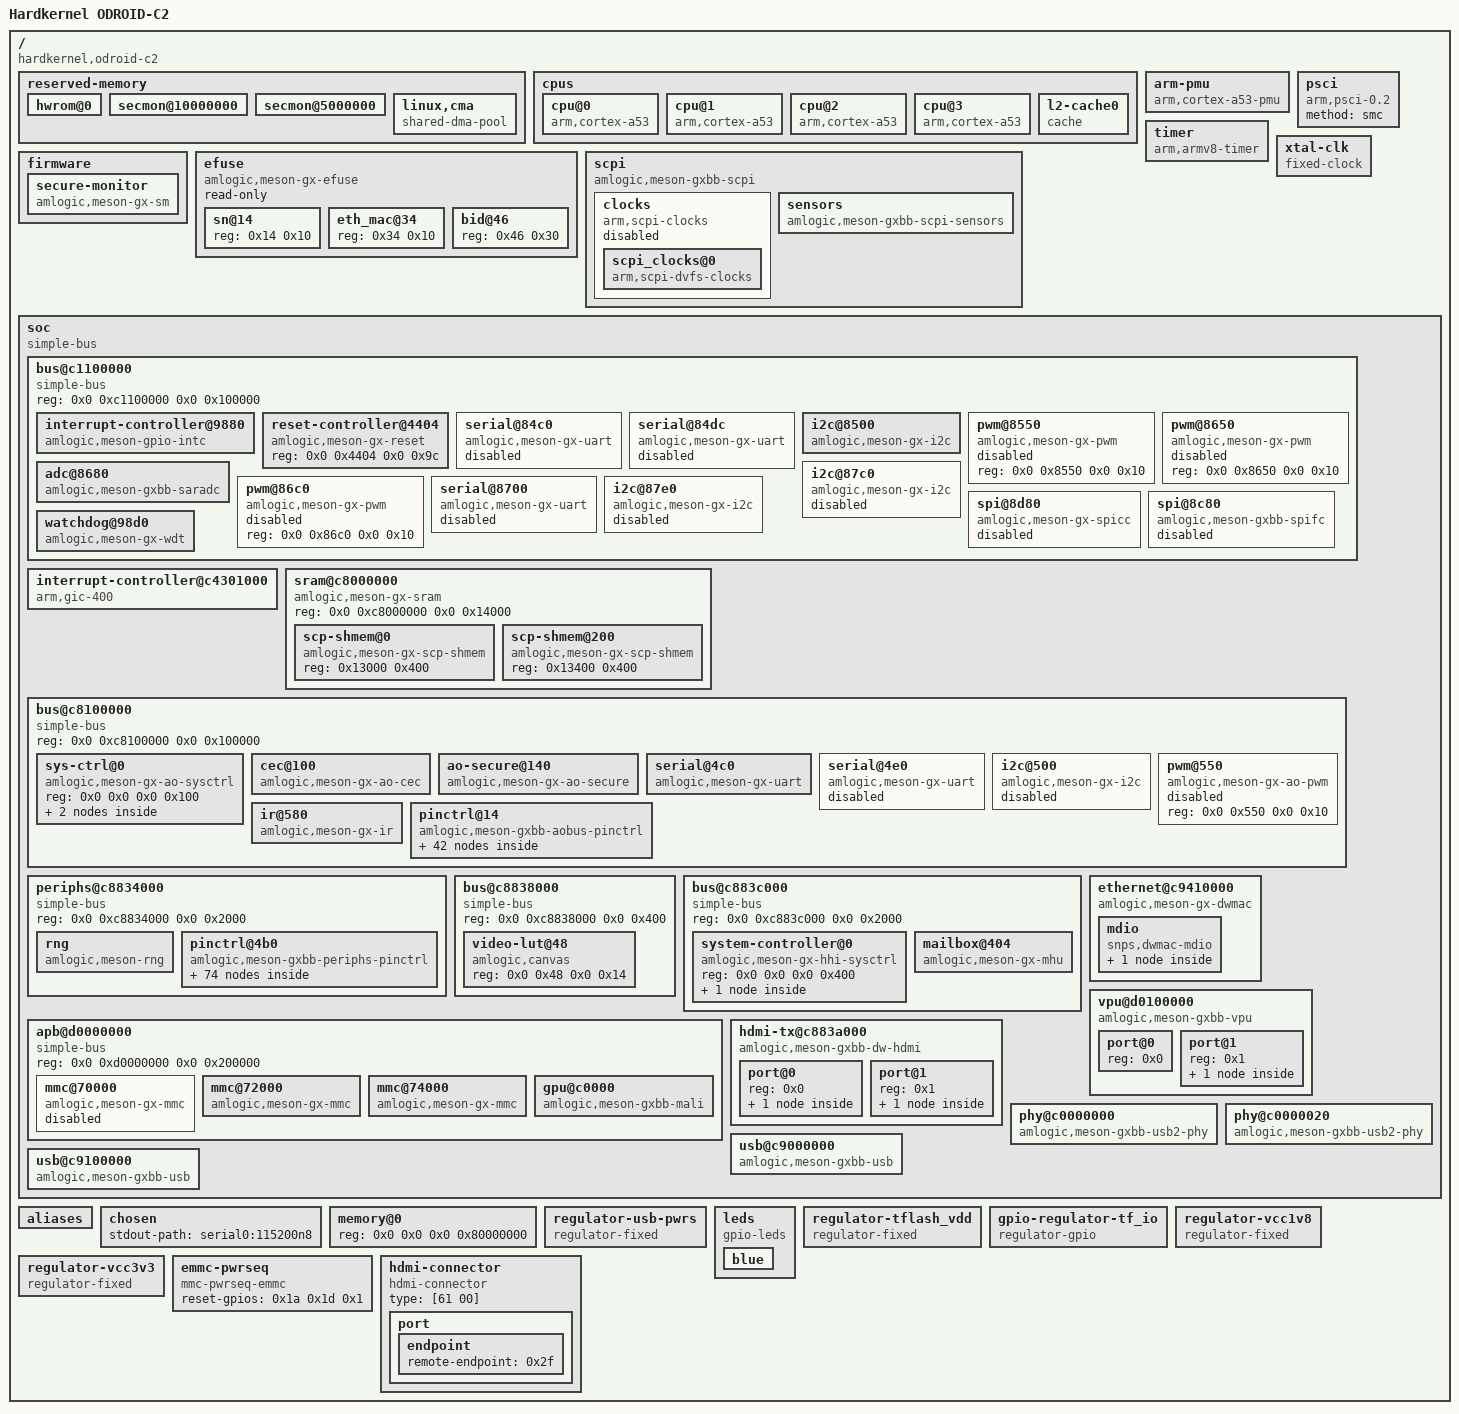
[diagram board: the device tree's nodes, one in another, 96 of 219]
/*
 * The code contained herein is licensed under the GNU General Public
 * License. You may obtain a copy of the GNU General Public License
 * Version 2 or later at the following locations:
 *
 * http://www.opensource.org/licenses/gpl-license.html
 * http://www.gnu.org/copyleft/gpl.html
 *
 * @TAG(OTHER_GPL)
 */

/dts-v1/;

/ {
	interrupt-parent = <0x1>;
	#address-cells = <0x2>;
	#size-cells = <0x2>;
	compatible = "hardkernel,odroid-c2", "amlogic,meson-gxbb";
	model = "Hardkernel ODROID-C2";

	reserved-memory {
		#address-cells = <0x2>;
		#size-cells = <0x2>;
		ranges;

		hwrom@0 {
			reg = <0x0 0x0 0x0 0x1000000>;
			no-map;
		};

		secmon@10000000 {
			reg = <0x0 0x10000000 0x0 0x200000>;
			no-map;
		};

		secmon@5000000 {
			reg = <0x0 0x5000000 0x0 0x300000>;
			no-map;
		};

		linux,cma {
			compatible = "shared-dma-pool";
			reusable;
			size = <0x0 0x10000000>;
			alignment = <0x0 0x400000>;
			linux,cma-default;
		};
	};

	cpus {
		#address-cells = <0x2>;
		#size-cells = <0x0>;

		cpu@0 {
			device_type = "cpu";
			compatible = "arm,cortex-a53", "arm,armv8";
			reg = <0x0 0x0>;
			enable-method = "psci";
			next-level-cache = <0x2>;
			clocks = <0x3 0x0>;
			phandle = <0x4>;
		};

		cpu@1 {
			device_type = "cpu";
			compatible = "arm,cortex-a53", "arm,armv8";
			reg = <0x0 0x1>;
			enable-method = "psci";
			next-level-cache = <0x2>;
			clocks = <0x3 0x0>;
			phandle = <0x5>;
		};

		cpu@2 {
			device_type = "cpu";
			compatible = "arm,cortex-a53", "arm,armv8";
			reg = <0x0 0x2>;
			enable-method = "psci";
			next-level-cache = <0x2>;
			clocks = <0x3 0x0>;
			phandle = <0x6>;
		};

		cpu@3 {
			device_type = "cpu";
			compatible = "arm,cortex-a53", "arm,armv8";
			reg = <0x0 0x3>;
			enable-method = "psci";
			next-level-cache = <0x2>;
			clocks = <0x3 0x0>;
			phandle = <0x7>;
		};

		l2-cache0 {
			compatible = "cache";
			phandle = <0x2>;
		};
	};

	arm-pmu {
		compatible = "arm,cortex-a53-pmu";
		interrupts = <0x0 0x89 0x4 0x0 0x8a 0x4 0x0 0x99 0x4 0x0 0x9a 0x4>;
		interrupt-affinity = <0x4 0x5 0x6 0x7>;
	};

	psci {
		compatible = "arm,psci-0.2";
		method = "smc";
	};

	timer {
		compatible = "arm,armv8-timer";
		interrupts = <0x1 0xd 0xff08 0x1 0xe 0xff08 0x1 0xb 0xff08 0x1 0xa 0xff08>;
	};

	xtal-clk {
		compatible = "fixed-clock";
		clock-frequency = <0x16e3600>;
		clock-output-names = "xtal";
		#clock-cells = <0x0>;
		phandle = <0xb>;
	};

	firmware {

		secure-monitor {
			compatible = "amlogic,meson-gx-sm", "amlogic,meson-gxbb-sm";
		};
	};

	efuse {
		compatible = "amlogic,meson-gx-efuse", "amlogic,meson-gxbb-efuse";
		#address-cells = <0x1>;
		#size-cells = <0x1>;
		read-only;

		sn@14 {
			reg = <0x14 0x10>;
		};

		eth_mac@34 {
			reg = <0x34 0x10>;
		};

		bid@46 {
			reg = <0x46 0x30>;
		};
	};

	scpi {
		compatible = "amlogic,meson-gxbb-scpi", "arm,scpi-pre-1.0";
		mboxes = <0x8 0x1 0x8 0x2>;
		shmem = <0x9 0xa>;

		clocks {
			compatible = "arm,scpi-clocks";
			status = "disabled";

			scpi_clocks@0 {
				compatible = "arm,scpi-dvfs-clocks";
				#clock-cells = <0x1>;
				clock-indices = <0x0>;
				clock-output-names = "vcpu";
				phandle = <0x3>;
			};
		};

		sensors {
			compatible = "amlogic,meson-gxbb-scpi-sensors", "arm,scpi-sensors";
			#thermal-sensor-cells = <0x1>;
		};
	};

	soc {
		compatible = "simple-bus";
		#address-cells = <0x2>;
		#size-cells = <0x2>;
		ranges;

		bus@c1100000 {
			compatible = "simple-bus";
			reg = <0x0 0xc1100000 0x0 0x100000>;
			#address-cells = <0x2>;
			#size-cells = <0x2>;
			ranges = <0x0 0x0 0x0 0xc1100000 0x0 0x100000>;

			interrupt-controller@9880 {
				compatible = "amlogic,meson-gpio-intc", "amlogic,meson-gxbb-gpio-intc";
				reg = <0x0 0x9880 0x0 0x10>;
				interrupt-controller;
				#interrupt-cells = <0x2>;
				amlogic,channel-interrupts = <0x40 0x41 0x42 0x43 0x44 0x45 0x46 0x47>;
				status = "okay";
				phandle = <0x1b>;
			};

			reset-controller@4404 {
				compatible = "amlogic,meson-gx-reset", "amlogic,meson-gxbb-reset";
				reg = <0x0 0x4404 0x0 0x9c>;
				#reset-cells = <0x1>;
				phandle = <0xf>;
			};

			serial@84c0 {
				compatible = "amlogic,meson-gx-uart";
				reg = <0x0 0x84c0 0x0 0x18>;
				interrupts = <0x0 0x1a 0x1>;
				status = "disabled";
				clocks = <0xb 0xc 0x1a 0xb>;
				clock-names = "xtal", "pclk", "baud";
			};

			serial@84dc {
				compatible = "amlogic,meson-gx-uart";
				reg = <0x0 0x84dc 0x0 0x18>;
				interrupts = <0x0 0x4b 0x1>;
				status = "disabled";
				clocks = <0xb 0xc 0x30 0xb>;
				clock-names = "xtal", "pclk", "baud";
			};

			i2c@8500 {
				compatible = "amlogic,meson-gx-i2c", "amlogic,meson-gxbb-i2c";
				reg = <0x0 0x8500 0x0 0x20>;
				interrupts = <0x0 0x15 0x1>;
				#address-cells = <0x1>;
				#size-cells = <0x0>;
				status = "okay";
				clocks = <0xc 0x16>;
				pinctrl-0 = <0xd>;
				pinctrl-names = "default";
			};

			pwm@8550 {
				compatible = "amlogic,meson-gx-pwm", "amlogic,meson-gxbb-pwm";
				reg = <0x0 0x8550 0x0 0x10>;
				#pwm-cells = <0x3>;
				status = "disabled";
			};

			pwm@8650 {
				compatible = "amlogic,meson-gx-pwm", "amlogic,meson-gxbb-pwm";
				reg = <0x0 0x8650 0x0 0x10>;
				#pwm-cells = <0x3>;
				status = "disabled";
			};

			adc@8680 {
				compatible = "amlogic,meson-gxbb-saradc", "amlogic,meson-saradc";
				reg = <0x0 0x8680 0x0 0x34>;
				#io-channel-cells = <0x1>;
				interrupts = <0x0 0x49 0x1>;
				status = "okay";
				clocks = <0xb 0xc 0x17 0xc 0x61 0xc 0x62>;
				clock-names = "clkin", "core", "adc_clk", "adc_sel";
				vref-supply = <0xe>;
			};

			pwm@86c0 {
				compatible = "amlogic,meson-gx-pwm", "amlogic,meson-gxbb-pwm";
				reg = <0x0 0x86c0 0x0 0x10>;
				#pwm-cells = <0x3>;
				status = "disabled";
			};

			serial@8700 {
				compatible = "amlogic,meson-gx-uart";
				reg = <0x0 0x8700 0x0 0x18>;
				interrupts = <0x0 0x5d 0x1>;
				status = "disabled";
				clocks = <0xb 0xc 0x44 0xb>;
				clock-names = "xtal", "pclk", "baud";
			};

			i2c@87c0 {
				compatible = "amlogic,meson-gx-i2c", "amlogic,meson-gxbb-i2c";
				reg = <0x0 0x87c0 0x0 0x20>;
				interrupts = <0x0 0xd6 0x1>;
				#address-cells = <0x1>;
				#size-cells = <0x0>;
				status = "disabled";
				clocks = <0xc 0x16>;
			};

			i2c@87e0 {
				compatible = "amlogic,meson-gx-i2c", "amlogic,meson-gxbb-i2c";
				reg = <0x0 0x87e0 0x0 0x20>;
				interrupts = <0x0 0xd7 0x1>;
				#address-cells = <0x1>;
				#size-cells = <0x0>;
				status = "disabled";
				clocks = <0xc 0x16>;
			};

			spi@8d80 {
				compatible = "amlogic,meson-gx-spicc";
				reg = <0x0 0x8d80 0x0 0x80>;
				interrupts = <0x0 0x51 0x4>;
				#address-cells = <0x1>;
				#size-cells = <0x0>;
				status = "disabled";
				clocks = <0xc 0x15>;
				clock-names = "core";
				resets = <0xf 0xc1>;
				num-cs = <0x1>;
			};

			spi@8c80 {
				compatible = "amlogic,meson-gxbb-spifc";
				reg = <0x0 0x8c80 0x0 0x80>;
				#address-cells = <0x1>;
				#size-cells = <0x0>;
				status = "disabled";
				clocks = <0xc 0x22>;
			};

			watchdog@98d0 {
				compatible = "amlogic,meson-gx-wdt", "amlogic,meson-gxbb-wdt";
				reg = <0x0 0x98d0 0x0 0x10>;
				clocks = <0xb>;
			};
		};

		interrupt-controller@c4301000 {
			compatible = "arm,gic-400";
			reg = <0x0 0xc4301000 0x0 0x1000 0x0 0xc4302000 0x0 0x2000 0x0 0xc4304000 0x0 0x2000 0x0 0xc4306000 0x0 0x2000>;
			interrupt-controller;
			interrupts = <0x1 0x9 0xff04>;
			#interrupt-cells = <0x3>;
			#address-cells = <0x0>;
			phandle = <0x1>;
		};

		sram@c8000000 {
			compatible = "amlogic,meson-gx-sram", "amlogic,meson-gxbb-sram", "mmio-sram";
			reg = <0x0 0xc8000000 0x0 0x14000>;
			#address-cells = <0x1>;
			#size-cells = <0x1>;
			ranges = <0x0 0x0 0xc8000000 0x14000>;

			scp-shmem@0 {
				compatible = "amlogic,meson-gx-scp-shmem", "amlogic,meson-gxbb-scp-shmem";
				reg = <0x13000 0x400>;
				phandle = <0x9>;
			};

			scp-shmem@200 {
				compatible = "amlogic,meson-gx-scp-shmem", "amlogic,meson-gxbb-scp-shmem";
				reg = <0x13400 0x400>;
				phandle = <0xa>;
			};
		};

		bus@c8100000 {
			compatible = "simple-bus";
			reg = <0x0 0xc8100000 0x0 0x100000>;
			#address-cells = <0x2>;
			#size-cells = <0x2>;
			ranges = <0x0 0x0 0x0 0xc8100000 0x0 0x100000>;

			sys-ctrl@0 {
				compatible = "amlogic,meson-gx-ao-sysctrl", "simple-mfd", "syscon";
				reg = <0x0 0x0 0x0 0x100>;

				power-controller-vpu {
					compatible = "amlogic,meson-gx-pwrc-vpu";
					#power-domain-cells = <0x0>;
					amlogic,hhi-sysctrl = <0x10>;
					resets = <0xf 0x5 0xf 0xa 0xf 0xd 0xf 0x25 0xf 0x84 0xf 0x85 0xf 0x86 0xf 0x87 0xf 0x89 0xf 0x8c 0xf 0x8d 0xf 0xe7>;
					clocks = <0xc 0x84 0xc 0x8c>;
					clock-names = "vpu", "vapb";
					assigned-clocks = <0xc 0x7e 0xc 0x80 0xc 0x84 0xc 0x85 0xc 0x87 0xc 0x8b>;
					assigned-clock-parents = <0xc 0x5 0x0 0xc 0x80 0xc 0x6 0x0 0xc 0x87>;
					assigned-clock-rates = <0x0 0x27bc86aa 0x0 0x0 0xee6b280 0x0>;
					phandle = <0x25>;
				};

				clock-controller {
					compatible = "amlogic,meson-gxbb-aoclkc", "amlogic,meson-gx-aoclkc";
					#clock-cells = <0x1>;
					#reset-cells = <0x1>;
					phandle = <0x11>;
				};
			};

			cec@100 {
				compatible = "amlogic,meson-gx-ao-cec";
				reg = <0x0 0x100 0x0 0x14>;
				interrupts = <0x0 0xc7 0x1>;
				clocks = <0x11 0x6>;
				clock-names = "core";
				status = "okay";
				pinctrl-0 = <0x12>;
				pinctrl-names = "default";
				hdmi-phandle = <0x13>;
			};

			ao-secure@140 {
				compatible = "amlogic,meson-gx-ao-secure", "syscon";
				reg = <0x0 0x140 0x0 0x140>;
				amlogic,has-chip-id;
			};

			serial@4c0 {
				compatible = "amlogic,meson-gx-uart", "amlogic,meson-ao-uart";
				reg = <0x0 0x4c0 0x0 0x18>;
				interrupts = <0x0 0xc1 0x1>;
				status = "okay";
				clocks = <0xb 0x11 0x3 0xb>;
				clock-names = "xtal", "pclk", "baud";
				pinctrl-0 = <0x14>;
				pinctrl-names = "default";
			};

			serial@4e0 {
				compatible = "amlogic,meson-gx-uart", "amlogic,meson-ao-uart";
				reg = <0x0 0x4e0 0x0 0x18>;
				interrupts = <0x0 0xc5 0x1>;
				status = "disabled";
				clocks = <0xb 0x11 0x4 0xb>;
				clock-names = "xtal", "pclk", "baud";
			};

			i2c@500 {
				compatible = "amlogic,meson-gx-i2c", "amlogic,meson-gxbb-i2c";
				reg = <0x0 0x500 0x0 0x20>;
				interrupts = <0x0 0xc3 0x1>;
				#address-cells = <0x1>;
				#size-cells = <0x0>;
				status = "disabled";
				clocks = <0xc 0x5d>;
			};

			pwm@550 {
				compatible = "amlogic,meson-gx-ao-pwm", "amlogic,meson-gxbb-ao-pwm";
				reg = <0x0 0x550 0x0 0x10>;
				#pwm-cells = <0x3>;
				status = "disabled";
			};

			ir@580 {
				compatible = "amlogic,meson-gx-ir", "amlogic,meson-gxbb-ir";
				reg = <0x0 0x580 0x0 0x40>;
				interrupts = <0x0 0xc4 0x1>;
				status = "okay";
				pinctrl-0 = <0x15>;
				pinctrl-names = "default";
			};

			pinctrl@14 {
				compatible = "amlogic,meson-gxbb-aobus-pinctrl";
				#address-cells = <0x2>;
				#size-cells = <0x2>;
				ranges;
				gpio-line-names = "UART TX", "UART RX", "VCCK En", "TF 3V3/1V8 En", "USB HUB nRESET", "USB OTG Power En", "J7 Header Pin2", "IR In", "J7 Header Pin4", "J7 Header Pin6", "J7 Header Pin5", "J7 Header Pin7", "HDMI CEC", "SYS LED", "";
				phandle = <0x16>;

				bank@14 {
					reg = <0x0 0x14 0x0 0x8 0x0 0x2c 0x0 0x4 0x0 0x24 0x0 0x8>;
					reg-names = "mux", "pull", "gpio";
					gpio-controller;
					#gpio-cells = <0x2>;
					gpio-ranges = <0x16 0x0 0x0 0xe>;
					phandle = <0x2e>;

					usb-hub {
						gpio-hog;
						gpios = <0x4 0x0>;
						output-high;
						line-name = "usb-hub-reset";
					};
				};

				uart_ao_a {
					phandle = <0x14>;

					mux {
						groups = "uart_tx_ao_a", "uart_rx_ao_a";
						function = "uart_ao";
					};
				};

				uart_ao_a_cts_rts {

					mux {
						groups = "uart_cts_ao_a", "uart_rts_ao_a";
						function = "uart_ao";
					};
				};

				uart_ao_b {

					mux {
						groups = "uart_tx_ao_b", "uart_rx_ao_b";
						function = "uart_ao_b";
					};
				};

				uart_ao_b_cts_rts {

					mux {
						groups = "uart_cts_ao_b", "uart_rts_ao_b";
						function = "uart_ao_b";
					};
				};

				remote_input_ao {
					phandle = <0x15>;

					mux {
						groups = "remote_input_ao";
						function = "remote_input_ao";
					};
				};

				i2c_ao {

					mux {
						groups = "i2c_sck_ao", "i2c_sda_ao";
						function = "i2c_ao";
					};
				};

				pwm_ao_a_3 {

					mux {
						groups = "pwm_ao_a_3";
						function = "pwm_ao_a_3";
					};
				};

				pwm_ao_a_6 {

					mux {
						groups = "pwm_ao_a_6";
						function = "pwm_ao_a_6";
					};
				};

				pwm_ao_a_12 {

					mux {
						groups = "pwm_ao_a_12";
						function = "pwm_ao_a_12";
					};
				};

				pwm_ao_b {

					mux {
						groups = "pwm_ao_b";
						function = "pwm_ao_b";
					};
				};

				i2s_am_clk {

					mux {
						groups = "i2s_am_clk";
						function = "i2s_out_ao";
					};
				};

				i2s_out_ao_clk {

					mux {
						groups = "i2s_out_ao_clk";
						function = "i2s_out_ao";
					};
				};

				i2s_out_lr_clk {

					mux {
						groups = "i2s_out_lr_clk";
						function = "i2s_out_ao";
					};
				};

				i2s_out_ch01_ao {

					mux {
						groups = "i2s_out_ch01_ao";
						function = "i2s_out_ao";
					};
				};

				i2s_out_ch23_ao {

					mux {
						groups = "i2s_out_ch23_ao";
						function = "i2s_out_ao";
					};
				};

				i2s_out_ch45_ao {

					mux {
						groups = "i2s_out_ch45_ao";
						function = "i2s_out_ao";
					};
				};

				spdif_out_ao_6 {

					mux {
						groups = "spdif_out_ao_6";
						function = "spdif_out_ao";
					};
				};

				spdif_out_ao_13 {

					mux {
						groups = "spdif_out_ao_13";
						function = "spdif_out_ao";
					};
				};

				ao_cec {
					phandle = <0x12>;

					mux {
						groups = "ao_cec";
						function = "cec_ao";
					};
				};

				ee_cec {

					mux {
						groups = "ee_cec";
						function = "cec_ao";
					};
				};
			};
		};

		periphs@c8834000 {
			compatible = "simple-bus";
			reg = <0x0 0xc8834000 0x0 0x2000>;
			#address-cells = <0x2>;
			#size-cells = <0x2>;
			ranges = <0x0 0x0 0x0 0xc8834000 0x0 0x2000>;

			rng {
				compatible = "amlogic,meson-rng";
				reg = <0x0 0x0 0x0 0x4>;
				clocks = <0xc 0x19>;
				clock-names = "core";
			};

			pinctrl@4b0 {
				compatible = "amlogic,meson-gxbb-periphs-pinctrl";
				#address-cells = <0x2>;
				#size-cells = <0x2>;
				ranges;
				gpio-line-names = "Eth MDIO", "Eth MDC", "Eth RGMII RX Clk", "Eth RX DV", "Eth RX D0", "Eth RX D1", "Eth RX D2", "Eth RX D3", "Eth RGMII TX Clk", "Eth TX En", "Eth TX D0", "Eth TX D1", "Eth TX D2", "Eth TX D3", "Eth PHY nRESET", "Eth PHY Intc", "HDMI HPD", "HDMI DDC SDA", "HDMI DDC SCL", "", "eMMC D0", "eMMC D1", "eMMC D2", "eMMC D3", "eMMC D4", "eMMC D5", "eMMC D6", "eMMC D7", "eMMC Clk", "eMMC Reset", "eMMC CMD", "", "", "", "", "", "", "", "SDCard D1", "SDCard D0", "SDCard CLK", "SDCard CMD", "SDCard D3", "SDCard D2", "SDCard Det", "", "", "", "", "", "", "", "", "", "", "", "", "", "", "", "", "", "", "", "", "", "", "", "", "I2C A SDA", "I2C A SCK", "I2C B SDA", "I2C B SCK", "PWM D", "PWM B", "Revision Bit0", "Revision Bit1", "", "J2 Header Pin35", "", "", "", "J2 Header Pin36", "J2 Header Pin31", "", "", "", "TF VDD En", "J2 Header Pin32", "J2 Header Pin26", "", "", "J2 Header Pin29", "J2 Header Pin24", "J2 Header Pin23", "J2 Header Pin22", "J2 Header Pin21", "J2 Header Pin18", "J2 Header Pin33", "J2 Header Pin19", "J2 Header Pin16", "J2 Header Pin15", "J2 Header Pin12", "J2 Header Pin13", "J2 Header Pin8", "J2 Header Pin10", "", "", "", "", "", "J2 Header Pin11", "", "J2 Header Pin7", "", "", "", "", "";
				phandle = <0x17>;

				bank@4b0 {
					reg = <0x0 0x4b0 0x0 0x28 0x0 0x4e8 0x0 0x14 0x0 0x520 0x0 0x14 0x0 0x430 0x0 0x40>;
					reg-names = "mux", "pull", "pull-enable", "gpio";
					gpio-controller;
					#gpio-cells = <0x2>;
					gpio-ranges = <0x17 0x0 0x0 0x77>;
					phandle = <0x1a>;
				};

				emmc {
					phandle = <0x20>;

					mux {
						groups = "emmc_nand_d07", "emmc_cmd", "emmc_clk";
						function = "emmc";
					};
				};

				emmc-ds {
					phandle = <0x21>;

					mux {
						groups = "emmc_ds";
						function = "emmc";
					};
				};

				emmc_clk_gate {
					phandle = <0x22>;

					mux {
						groups = "BOOT_8";
						function = "gpio_periphs";
					};

					cfg-pull-down {
						pins = "BOOT_8";
						bias-pull-down;
					};
				};

				nor {

					mux {
						groups = "nor_d", "nor_q", "nor_c", "nor_cs";
						function = "nor";
					};
				};

				spi-pins {

					mux {
						groups = "spi_miso", "spi_mosi", "spi_sclk";
						function = "spi";
					};
				};

				spi-ss0 {

					mux {
						groups = "spi_ss0";
						function = "spi";
					};
				};

				sdcard {
					phandle = <0x1c>;

					mux {
						groups = "sdcard_d0", "sdcard_d1", "sdcard_d2", "sdcard_d3", "sdcard_cmd", "sdcard_clk";
						function = "sdcard";
					};
				};

				sdcard_clk_gate {
					phandle = <0x1d>;

					mux {
						groups = "CARD_2";
						function = "gpio_periphs";
					};

					cfg-pull-down {
						pins = "CARD_2";
						bias-pull-down;
					};
				};

				sdio {

					mux {
						groups = "sdio_d0", "sdio_d1", "sdio_d2", "sdio_d3", "sdio_cmd", "sdio_clk";
						function = "sdio";
					};
				};

				sdio_clk_gate {

					mux {
						groups = "GPIOX_4";
						function = "gpio_periphs";
					};

					cfg-pull-down {
						pins = "GPIOX_4";
						bias-pull-down;
					};
				};

				sdio_irq {

					mux {
						groups = "sdio_irq";
						function = "sdio";
					};
				};

				uart_a {

					mux {
						groups = "uart_tx_a", "uart_rx_a";
						function = "uart_a";
					};
				};

				uart_a_cts_rts {

					mux {
						groups = "uart_cts_a", "uart_rts_a";
						function = "uart_a";
					};
				};

				uart_b {

					mux {
						groups = "uart_tx_b", "uart_rx_b";
						function = "uart_b";
					};
				};

				uart_b_cts_rts {

					mux {
						groups = "uart_cts_b", "uart_rts_b";
						function = "uart_b";
					};
				};

				uart_c {

					mux {
						groups = "uart_tx_c", "uart_rx_c";
						function = "uart_c";
					};
				};

				uart_c_cts_rts {

					mux {
						groups = "uart_cts_c", "uart_rts_c";
						function = "uart_c";
					};
				};

				i2c_a {
					phandle = <0xd>;

					mux {
						groups = "i2c_sck_a", "i2c_sda_a";
						function = "i2c_a";
					};
				};

				i2c_b {

					mux {
						groups = "i2c_sck_b", "i2c_sda_b";
						function = "i2c_b";
					};
				};

				i2c_c {

					mux {
						groups = "i2c_sck_c", "i2c_sda_c";
						function = "i2c_c";
					};
				};

				eth-rgmii {
					phandle = <0x18>;

					mux {
						groups = "eth_mdio", "eth_mdc", "eth_clk_rx_clk", "eth_rx_dv", "eth_rxd0", "eth_rxd1", "eth_rxd2", "eth_rxd3", "eth_rgmii_tx_clk", "eth_tx_en", "eth_txd0", "eth_txd1", "eth_txd2", "eth_txd3";
						function = "eth";
					};
				};

				eth-rmii {

					mux {
						groups = "eth_mdio", "eth_mdc", "eth_clk_rx_clk", "eth_rx_dv", "eth_rxd0", "eth_rxd1", "eth_tx_en", "eth_txd0", "eth_txd1";
						function = "eth";
					};
				};

				pwm_a_x {

					mux {
						groups = "pwm_a_x";
						function = "pwm_a_x";
					};
				};

				pwm_a_y {

					mux {
						groups = "pwm_a_y";
						function = "pwm_a_y";
					};
				};

				pwm_b {

					mux {
						groups = "pwm_b";
						function = "pwm_b";
					};
				};

				pwm_d {

					mux {
						groups = "pwm_d";
						function = "pwm_d";
					};
				};

				pwm_e {

					mux {
						groups = "pwm_e";
						function = "pwm_e";
					};
				};

				pwm_f_x {

					mux {
						groups = "pwm_f_x";
						function = "pwm_f_x";
					};
				};

				pwm_f_y {

					mux {
						groups = "pwm_f_y";
						function = "pwm_f_y";
					};
				};

				hdmi_hpd {
					phandle = <0x27>;

					mux {
						groups = "hdmi_hpd";
						function = "hdmi_hpd";
					};
				};

				hdmi_i2c {
					phandle = <0x28>;

					mux {
						groups = "hdmi_sda", "hdmi_scl";
						function = "hdmi_i2c";
					};
				};

				i2sout_ch23_y {

					mux {
						groups = "i2sout_ch23_y";
						function = "i2s_out";
					};
				};

				i2sout_ch45_y {

					mux {
						groups = "i2sout_ch45_y";
						function = "i2s_out";
					};
				};

				i2sout_ch67_y {

					mux {
						groups = "i2sout_ch67_y";
						function = "i2s_out";
					};
				};

				spdif_out_y {

					mux {
						groups = "spdif_out_y";
						function = "spdif_out";
					};
				};
			};
		};

		bus@c8838000 {
			compatible = "simple-bus";
			reg = <0x0 0xc8838000 0x0 0x400>;
			#address-cells = <0x2>;
			#size-cells = <0x2>;
			ranges = <0x0 0x0 0x0 0xc8838000 0x0 0x400>;

			video-lut@48 {
				compatible = "amlogic,canvas";
				reg = <0x0 0x48 0x0 0x14>;
			};
		};

		bus@c883c000 {
			compatible = "simple-bus";
			reg = <0x0 0xc883c000 0x0 0x2000>;
			#address-cells = <0x2>;
			#size-cells = <0x2>;
			ranges = <0x0 0x0 0x0 0xc883c000 0x0 0x2000>;

			system-controller@0 {
				compatible = "amlogic,meson-gx-hhi-sysctrl", "simple-mfd", "syscon";
				reg = <0x0 0x0 0x0 0x400>;
				phandle = <0x10>;

				clock-controller {
					compatible = "amlogic,gxbb-clkc";
					#clock-cells = <0x1>;
					phandle = <0xc>;
				};
			};

			mailbox@404 {
				compatible = "amlogic,meson-gx-mhu", "amlogic,meson-gxbb-mhu";
				reg = <0x0 0x404 0x0 0x4c>;
				interrupts = <0x0 0xd0 0x1 0x0 0xd1 0x1 0x0 0xd2 0x1>;
				#mbox-cells = <0x1>;
				phandle = <0x8>;
			};
		};

		ethernet@c9410000 {
			compatible = "amlogic,meson-gx-dwmac", "amlogic,meson-gxbb-dwmac", "snps,dwmac";
			reg = <0x0 0xc9410000 0x0 0x10000 0x0 0xc8834540 0x0 0x4>;
			interrupts = <0x0 0x8 0x1>;
			interrupt-names = "macirq";
			status = "okay";
			clocks = <0xc 0x24 0xc 0x4 0xc 0xf>;
			clock-names = "stmmaceth", "clkin0", "clkin1";
			pinctrl-0 = <0x18>;
			pinctrl-names = "default";
			phy-handle = <0x19>;
			phy-mode = "rgmii";
			snps,reset-gpio = <0x1a 0xe 0x0>;
			snps,reset-delays-us = <0x0 0x2710 0xf4240>;
			snps,reset-active-low;
			amlogic,tx-delay-ns = <0x2>;

			mdio {
				compatible = "snps,dwmac-mdio";
				#address-cells = <0x1>;
				#size-cells = <0x0>;

				ethernet-phy@0 {
					reg = <0x0>;
					interrupt-parent = <0x1b>;
					interrupts = <0x1d 0x8>;
					eee-broken-1000t;
					phandle = <0x19>;
				};
			};
		};

		apb@d0000000 {
			compatible = "simple-bus";
			reg = <0x0 0xd0000000 0x0 0x200000>;
			#address-cells = <0x2>;
			#size-cells = <0x2>;
			ranges = <0x0 0x0 0x0 0xd0000000 0x0 0x200000>;

			mmc@70000 {
				compatible = "amlogic,meson-gx-mmc", "amlogic,meson-gxbb-mmc";
				reg = <0x0 0x70000 0x0 0x800>;
				interrupts = <0x0 0xd8 0x1>;
				status = "disabled";
				clocks = <0xc 0x5e 0xc 0x77 0xc 0x4>;
				clock-names = "core", "clkin0", "clkin1";
				resets = <0xf 0x2c>;
			};

			mmc@72000 {
				compatible = "amlogic,meson-gx-mmc", "amlogic,meson-gxbb-mmc";
				reg = <0x0 0x72000 0x0 0x800>;
				interrupts = <0x0 0xd9 0x1>;
				status = "okay";
				clocks = <0xc 0x5f 0xc 0x7a 0xc 0x4>;
				clock-names = "core", "clkin0", "clkin1";
				resets = <0xf 0x2d>;
				pinctrl-0 = <0x1c>;
				pinctrl-1 = <0x1d>;
				pinctrl-names = "default", "clk-gate";
				bus-width = <0x4>;
				cap-sd-highspeed;
				max-frequency = <0x5f5e100>;
				disable-wp;
				cd-gpios = <0x1a 0x2c 0x0>;
				cd-inverted;
				vmmc-supply = <0x1e>;
				vqmmc-supply = <0x1f>;
			};

			mmc@74000 {
				compatible = "amlogic,meson-gx-mmc", "amlogic,meson-gxbb-mmc";
				reg = <0x0 0x74000 0x0 0x800>;
				interrupts = <0x0 0xda 0x1>;
				status = "okay";
				clocks = <0xc 0x60 0xc 0x7d 0xc 0x4>;
				clock-names = "core", "clkin0", "clkin1";
				resets = <0xf 0x2e>;
				pinctrl-0 = <0x20 0x21>;
				pinctrl-1 = <0x22>;
				pinctrl-names = "default", "clk-gate";
				bus-width = <0x8>;
				max-frequency = <0x5f5e100>;
				non-removable;
				disable-wp;
				cap-mmc-highspeed;
				mmc-ddr-1_8v;
				mmc-hs200-1_8v;
				mmc-pwrseq = <0x23>;
				vmmc-supply = <0x24>;
				vqmmc-supply = <0xe>;
			};

			gpu@c0000 {
				compatible = "amlogic,meson-gxbb-mali", "arm,mali-450";
				reg = <0x0 0xc0000 0x0 0x40000>;
				interrupts = <0x0 0xa0 0x4 0x0 0xa1 0x4 0x0 0xa2 0x4 0x0 0xa3 0x4 0x0 0xa4 0x4 0x0 0xa5 0x4 0x0 0xa6 0x4 0x0 0xa7 0x4 0x0 0xa8 0x4 0x0 0xa9 0x4>;
				interrupt-names = "gp", "gpmmu", "pp", "pmu", "pp0", "ppmmu0", "pp1", "ppmmu1", "pp2", "ppmmu2";
				clocks = <0xc 0xc 0xc 0x6a>;
				clock-names = "bus", "core";
				assigned-clocks = <0xc 0x9 0xc 0x64 0xc 0x66 0xc 0x6a>;
				assigned-clock-parents = <0x0 0xc 0x9 0x0 0xc 0x66>;
				assigned-clock-rates = <0x2c588a00 0x0 0x2c588a00 0x0>;
			};
		};

		vpu@d0100000 {
			compatible = "amlogic,meson-gxbb-vpu", "amlogic,meson-gx-vpu";
			reg = <0x0 0xd0100000 0x0 0x100000 0x0 0xc883c000 0x0 0x1000 0x0 0xc8838000 0x0 0x1000>;
			reg-names = "vpu", "hhi", "dmc";
			interrupts = <0x0 0x3 0x1>;
			#address-cells = <0x1>;
			#size-cells = <0x0>;
			power-domains = <0x25>;

			port@0 {
				reg = <0x0>;
			};

			port@1 {
				reg = <0x1>;

				endpoint {
					remote-endpoint = <0x26>;
					phandle = <0x29>;
				};
			};
		};

		hdmi-tx@c883a000 {
			compatible = "amlogic,meson-gxbb-dw-hdmi", "amlogic,meson-gx-dw-hdmi";
			reg = <0x0 0xc883a000 0x0 0x1c>;
			interrupts = <0x0 0x39 0x1>;
			#address-cells = <0x1>;
			#size-cells = <0x0>;
			status = "okay";
			resets = <0xf 0x13 0xf 0x4f 0xf 0x42>;
			reset-names = "hdmitx_apb", "hdmitx", "hdmitx_phy";
			clocks = <0xc 0x3f 0xc 0xc 0xc 0x4d>;
			clock-names = "isfr", "iahb", "venci";
			pinctrl-0 = <0x27 0x28>;
			pinctrl-names = "default";
			phandle = <0x13>;

			port@0 {
				reg = <0x0>;

				endpoint {
					remote-endpoint = <0x29>;
					phandle = <0x26>;
				};
			};

			port@1 {
				reg = <0x1>;

				endpoint {
					remote-endpoint = <0x2a>;
					phandle = <0x2f>;
				};
			};
		};

		phy@c0000000 {
			compatible = "amlogic,meson-gxbb-usb2-phy";
			#phy-cells = <0x0>;
			reg = <0x0 0xc0000000 0x0 0x20>;
			resets = <0xf 0x22>;
			clocks = <0xc 0x37 0xc 0x32>;
			clock-names = "usb_general", "usb";
			status = "okay";
			phy-supply = <0x2b>;
			phandle = <0x2c>;
		};

		phy@c0000020 {
			compatible = "amlogic,meson-gxbb-usb2-phy";
			#phy-cells = <0x0>;
			reg = <0x0 0xc0000020 0x0 0x20>;
			resets = <0xf 0x22>;
			clocks = <0xc 0x37 0xc 0x33>;
			clock-names = "usb_general", "usb";
			status = "okay";
			phy-supply = <0x2b>;
			phandle = <0x2d>;
		};

		usb@c9000000 {
			compatible = "amlogic,meson-gxbb-usb", "snps,dwc2";
			reg = <0x0 0xc9000000 0x0 0x40000>;
			interrupts = <0x0 0x1e 0x4>;
			clocks = <0xc 0x41>;
			clock-names = "otg";
			phys = <0x2c>;
			phy-names = "usb2-phy";
			dr_mode = "host";
			status = "okay";
		};

		usb@c9100000 {
			compatible = "amlogic,meson-gxbb-usb", "snps,dwc2";
			reg = <0x0 0xc9100000 0x0 0x40000>;
			interrupts = <0x0 0x1f 0x4>;
			clocks = <0xc 0x40>;
			clock-names = "otg";
			phys = <0x2d>;
			phy-names = "usb2-phy";
			dr_mode = "host";
			status = "okay";
		};
	};

	aliases {
		serial0 = "/soc/bus@c8100000/serial@4c0";
		ethernet0 = "/soc/ethernet@c9410000";
	};

	chosen {
		stdout-path = "serial0:115200n8";
	};

	memory@0 {
		device_type = "memory";
		reg = <0x0 0x0 0x0 0x80000000>;
	};

	regulator-usb-pwrs {
		compatible = "regulator-fixed";
		regulator-name = "USB_OTG_PWR";
		regulator-min-microvolt = <0x4c4b40>;
		regulator-max-microvolt = <0x4c4b40>;
		gpio = <0x2e 0x5 0x0>;
		enable-active-high;
		phandle = <0x2b>;
	};

	leds {
		compatible = "gpio-leds";

		blue {
			label = "c2:blue:alive";
			gpios = <0x2e 0xd 0x1>;
			linux,default-trigger = "heartbeat";
			default-state = "off";
		};
	};

	regulator-tflash_vdd {
		compatible = "regulator-fixed";
		regulator-name = "TFLASH_VDD";
		regulator-min-microvolt = <0x325aa0>;
		regulator-max-microvolt = <0x325aa0>;
		gpio = <0x1a 0x57 0x0>;
		enable-active-high;
		phandle = <0x1e>;
	};

	gpio-regulator-tf_io {
		compatible = "regulator-gpio";
		regulator-name = "TF_IO";
		regulator-min-microvolt = <0x1b7740>;
		regulator-max-microvolt = <0x325aa0>;
		gpios = <0x2e 0x3 0x0>;
		gpios-states = <0x0>;
		states = <0x325aa0 0x0 0x1b7740 0x1>;
		phandle = <0x1f>;
	};

	regulator-vcc1v8 {
		compatible = "regulator-fixed";
		regulator-name = "VCC1V8";
		regulator-min-microvolt = <0x1b7740>;
		regulator-max-microvolt = <0x1b7740>;
		phandle = <0xe>;
	};

	regulator-vcc3v3 {
		compatible = "regulator-fixed";
		regulator-name = "VCC3V3";
		regulator-min-microvolt = <0x325aa0>;
		regulator-max-microvolt = <0x325aa0>;
		phandle = <0x24>;
	};

	emmc-pwrseq {
		compatible = "mmc-pwrseq-emmc";
		reset-gpios = <0x1a 0x1d 0x1>;
		phandle = <0x23>;
	};

	hdmi-connector {
		compatible = "hdmi-connector";
		type = [61 00];

		port {

			endpoint {
				remote-endpoint = <0x2f>;
				phandle = <0x2a>;
			};
		};
	};
};
